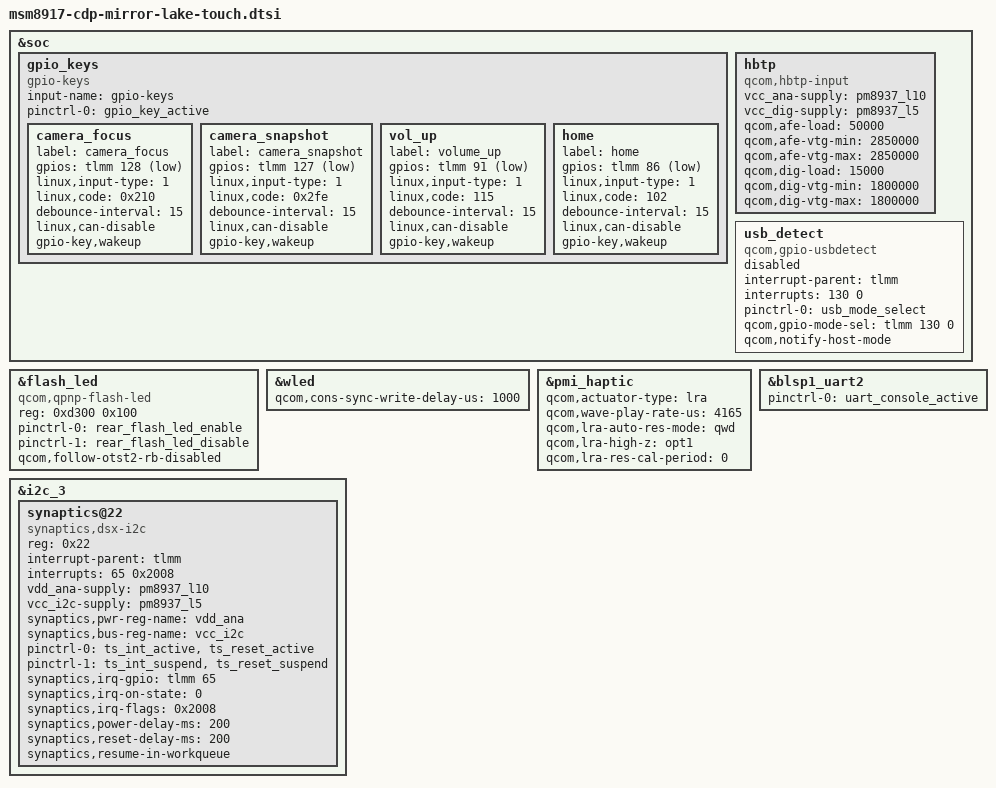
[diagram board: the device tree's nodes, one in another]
/*
 * Copyright (c) 2017-2018, The Linux Foundation. All rights reserved.
 *
 * This program is free software; you can redistribute it and/or modify
 * it under the terms of the GNU General Public License version 2 and
 * only version 2 as published by the Free Software Foundation.
 *
 * This program is distributed in the hope that it will be useful,
 * but WITHOUT ANY WARRANTY; without even the implied warranty of
 * MERCHANTABILITY or FITNESS FOR A PARTICULAR PURPOSE.  See the
 * GNU General Public License for more details.
 */

/* #include "msm8917-camera-sensor-cdp.dtsi"*/

&soc {
	gpio_keys {
		compatible = "gpio-keys";
		input-name = "gpio-keys";
		pinctrl-names = "default";
		pinctrl-0 = <&gpio_key_active>;

		camera_focus {
			label = "camera_focus";
			gpios = <&tlmm 128 0x1>;
			linux,input-type = <1>;
			linux,code = <0x210>;
			debounce-interval = <15>;
			linux,can-disable;
			gpio-key,wakeup;
		};

		camera_snapshot {
			label = "camera_snapshot";
			gpios = <&tlmm 127 0x1>;
			linux,input-type = <1>;
			linux,code = <0x2fe>;
			debounce-interval = <15>;
			linux,can-disable;
			gpio-key,wakeup;
		};

		vol_up {
			label = "volume_up";
			gpios = <&tlmm 91 0x1>;
			linux,input-type = <1>;
			linux,code = <115>;
			debounce-interval = <15>;
			linux,can-disable;
			gpio-key,wakeup;
		};

		home {
			label = "home";
			gpios = <&tlmm 86 0x1>;
			linux,input-type = <1>;
			linux,code = <102>;
			debounce-interval = <15>;
			linux,can-disable;
			gpio-key,wakeup;
		};
	};

	hbtp {
		compatible = "qcom,hbtp-input";
		vcc_ana-supply = <&pm8937_l10>;
		vcc_dig-supply = <&pm8937_l5>;
		qcom,afe-load = <50000>;
		qcom,afe-vtg-min = <2850000>;
		qcom,afe-vtg-max = <2850000>;
		qcom,dig-load = <15000>;
		qcom,dig-vtg-min = <1800000>;
		qcom,dig-vtg-max = <1800000>;
	};

	usb_detect {
		compatible = "qcom,gpio-usbdetect";
		interrupt-names = "vbus_det_irq";
		interrupt-parent = <&tlmm>;
		interrupts = <130 0>;
		pinctrl-names = "default";
		pinctrl-0 = <&usb_mode_select>;
		qcom,gpio-mode-sel = <&tlmm 130 0>;
		qcom,notify-host-mode;
		status = "disabled";
	};
};

&flash_led {
	compatible = "qcom,qpnp-flash-led";
	reg = <0xd300 0x100>;
	pinctrl-names = "flash_led_enable","flash_led_disable";
	pinctrl-0 = <&rear_flash_led_enable>;
	pinctrl-1 = <&rear_flash_led_disable>;
	qcom,follow-otst2-rb-disabled;
};

&wled {
	qcom,cons-sync-write-delay-us = <1000>;
};

&pmi_haptic{
	qcom,actuator-type = "lra";
	qcom,wave-play-rate-us = <4165>;
	qcom,lra-auto-res-mode = "qwd";
	qcom,lra-high-z = "opt1";
	qcom,lra-res-cal-period = <0>;
};

&blsp1_uart2 {
	status = "ok";
	pinctrl-names = "default";
	pinctrl-0 = <&uart_console_active>;
};
&i2c_3 {
	status = "okay";
	synaptics@22 {
		compatible = "synaptics,dsx-i2c";
		reg = <0x22>;
		interrupt-parent = <&tlmm>;
		interrupts = <65 0x2008>;
		vdd_ana-supply = <&pm8937_l10>;
		vcc_i2c-supply = <&pm8937_l5>;
		synaptics,pwr-reg-name = "vdd_ana";
		synaptics,bus-reg-name = "vcc_i2c";
		pinctrl-names = "pmx_ts_active","pmx_ts_suspend";
		pinctrl-0 = <&ts_int_active &ts_reset_active>;
		pinctrl-1 = <&ts_int_suspend &ts_reset_suspend>;
		synaptics,irq-gpio = <&tlmm 65 0x2008>;
		synaptics,irq-on-state = <0>;
		synaptics,irq-flags = <0x2008>;
		synaptics,power-delay-ms = <200>;
		synaptics,reset-delay-ms = <200>;
		synaptics,resume-in-workqueue;
	};
};
